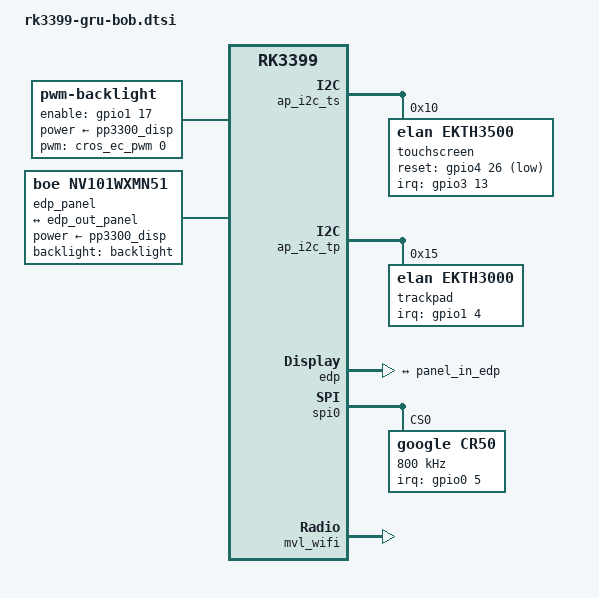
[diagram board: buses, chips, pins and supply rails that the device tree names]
/*
 * Google Gru-Bob board device tree source
 *
 * Copyright 2016 Google, Inc
 *
 * This file is dual-licensed: you can use it either under the terms
 * of the GPL or the X11 license, at your option. Note that this dual
 * licensing only applies to this file, and not this project as a
 * whole.
 *
 *  a) This file is free software; you can redistribute it and/or
 *     modify it under the terms of the GNU General Public License as
 *     published by the Free Software Foundation; either version 2 of the
 *     License, or (at your option) any later version.
 *
 *     This file is distributed in the hope that it will be useful,
 *     but WITHOUT ANY WARRANTY; without even the implied warranty of
 *     MERCHANTABILITY or FITNESS FOR A PARTICULAR PURPOSE.  See the
 *     GNU General Public License for more details.
 *
 *  Or, alternatively,
 *
 *  b) Permission is hereby granted, free of charge, to any person
 *     obtaining a copy of this software and associated documentation
 *     files (the "Software"), to deal in the Software without
 *     restriction, including without limitation the rights to use,
 *     copy, modify, merge, publish, distribute, sublicense, and/or
 *     sell copies of the Software, and to permit persons to whom the
 *     Software is furnished to do so, subject to the following
 *     conditions:
 *
 *     The above copyright notice and this permission notice shall be
 *     included in all copies or substantial portions of the Software.
 *
 *     THE SOFTWARE IS PROVIDED "AS IS", WITHOUT WARRANTY OF ANY KIND,
 *     EXPRESS OR IMPLIED, INCLUDING BUT NOT LIMITED TO THE WARRANTIES
 *     OF MERCHANTABILITY, FITNESS FOR A PARTICULAR PURPOSE AND
 *     NONINFRINGEMENT. IN NO EVENT SHALL THE AUTHORS OR COPYRIGHT
 *     HOLDERS BE LIABLE FOR ANY CLAIM, DAMAGES OR OTHER LIABILITY,
 *     WHETHER IN AN ACTION OF CONTRACT, TORT OR OTHERWISE, ARISING
 *     FROM, OUT OF OR IN CONNECTION WITH THE SOFTWARE OR THE USE OR
 *     OTHER DEALINGS IN THE SOFTWARE.
 */

#include "rk3399-gru.dtsi"

/ {
	backlight: backlight {
		compatible = "pwm-backlight";
		pwms = <&cros_ec_pwm 0>;
		brightness-levels-scale = <0x10000>;
		default-brightness-level = <0x828f>; /* arbitrary, ~51% */
		enable-gpios = <&gpio1 17 GPIO_ACTIVE_HIGH>;
		power-supply = <&pp3300_disp>;
		pinctrl-names = "default";
		pinctrl-0 = <&bl_en>;
		pwm-delay-us = <10000>;
	};

	edp_panel: edp-panel {
		compatible = "boe,nv101wxmn51", "simple-panel";
		backlight = <&backlight>;
		power-supply = <&pp3300_disp>;

		ports {
			panel_in_edp: endpoint {
				remote-endpoint = <&edp_out_panel>;
			};
		};
	};
};

&ap_i2c_ts {
	touchscreen: touchscreen@10 {
		compatible = "elan,ekth3500";
		reg = <0x10>;

		pinctrl-names = "default";
		pinctrl-0 = <&touch_int_l &touch_reset_l>;

		interrupt-parent = <&gpio3>;
		interrupts = <13 IRQ_TYPE_LEVEL_LOW>;

		reset-gpios = <&gpio4 26 GPIO_ACTIVE_LOW>;
	};
};

&ap_i2c_tp {
	trackpad: trackpad@15 {
		compatible = "elan,ekth3000";
		reg = <0x15>;

		pinctrl-names = "default";
		pinctrl-0 = <&trackpad_int_l>;

		interrupt-parent = <&gpio1>;
		interrupts = <4 IRQ_TYPE_LEVEL_LOW>;

		wakeup-source;
	};
};

&edp {
	status = "okay";

	ports {
		edp_out: port@1 {
			reg = <1>;
			#address-cells = <1>;
			#size-cells = <0>;

			edp_out_panel: endpoint@0 {
				reg = <0>;
				remote-endpoint = <&panel_in_edp>;
			};
		};
	};
};

&spi0 {
	status = "okay";

	cr50@0 {
		compatible = "google,cr50";

		interrupt-parent = <&gpio0>;
		interrupts = <5 IRQ_TYPE_EDGE_RISING>;

		pinctrl-names = "default";
		pinctrl-0 = <&h1_int_od_l>;

		reg = <0>;
		spi-max-frequency = <800000>;
	};
};

&target {
	temperature = <70000>;
};

&threshold {
	temperature = <65000>;
};

&mvl_wifi {
	marvell,caldata_00_txpwrlimit_2g_cfg_set = /bits/ 8 <
0x01 0x00 0x06 0x00 0x30 0x02 0x89 0x01 0x24 0x00 0x67 0x09 0x14 0x01 0x00 0x0d
0x01 0x0d 0x02 0x0d 0x03 0x0d 0x04 0x0d 0x05 0x0d 0x06 0x0d 0x07 0x0d 0x08 0x0d
0x09 0x0d 0x0a 0x0d 0x0b 0x0d 0x0c 0x0d 0x0d 0x0d 0x0e 0x0d 0x0f 0x0d 0x89 0x01
0x24 0x00 0x67 0x09 0x14 0x02 0x00 0x0d 0x01 0x0d 0x02 0x0d 0x03 0x0d 0x04 0x0d
0x05 0x0d 0x06 0x0d 0x07 0x0d 0x08 0x0d 0x09 0x0d 0x0a 0x0d 0x0b 0x0d 0x0c 0x0d
0x0d 0x0d 0x0e 0x0d 0x0f 0x0d 0x89 0x01 0x24 0x00 0x67 0x09 0x14 0x03 0x00 0x0d
0x01 0x0d 0x02 0x0d 0x03 0x0d 0x04 0x0d 0x05 0x0d 0x06 0x0d 0x07 0x0d 0x08 0x0d
0x09 0x0d 0x0a 0x0d 0x0b 0x0d 0x0c 0x0d 0x0d 0x0d 0x0e 0x0d 0x0f 0x0d 0x89 0x01
0x24 0x00 0x67 0x09 0x14 0x04 0x00 0x0d 0x01 0x0d 0x02 0x0d 0x03 0x0d 0x04 0x0d
0x05 0x0d 0x06 0x0d 0x07 0x0d 0x08 0x0d 0x09 0x0d 0x0a 0x0d 0x0b 0x0d 0x0c 0x0d
0x0d 0x0d 0x0e 0x0d 0x0f 0x0d 0x89 0x01 0x24 0x00 0x67 0x09 0x14 0x05 0x00 0x0d
0x01 0x0d 0x02 0x0d 0x03 0x0d 0x04 0x0d 0x05 0x0d 0x06 0x0d 0x07 0x0d 0x08 0x0d
0x09 0x0d 0x0a 0x0d 0x0b 0x0d 0x0c 0x0d 0x0d 0x0d 0x0e 0x0d 0x0f 0x0d 0x89 0x01
0x24 0x00 0x67 0x09 0x14 0x06 0x00 0x0d 0x01 0x0d 0x02 0x0d 0x03 0x0d 0x04 0x0d
0x05 0x0d 0x06 0x0d 0x07 0x0d 0x08 0x0d 0x09 0x0d 0x0a 0x0d 0x0b 0x0d 0x0c 0x0d
0x0d 0x0d 0x0e 0x0d 0x0f 0x0d 0x89 0x01 0x24 0x00 0x67 0x09 0x14 0x07 0x00 0x0d
0x01 0x0d 0x02 0x0d 0x03 0x0d 0x04 0x0d 0x05 0x0d 0x06 0x0d 0x07 0x0d 0x08 0x0d
0x09 0x0d 0x0a 0x0d 0x0b 0x0d 0x0c 0x0d 0x0d 0x0d 0x0e 0x0d 0x0f 0x0d 0x89 0x01
0x24 0x00 0x67 0x09 0x14 0x08 0x00 0x0d 0x01 0x0d 0x02 0x0d 0x03 0x0d 0x04 0x0d
0x05 0x0d 0x06 0x0d 0x07 0x0d 0x08 0x0d 0x09 0x0d 0x0a 0x0d 0x0b 0x0d 0x0c 0x0d
0x0d 0x0d 0x0e 0x0d 0x0f 0x0d 0x89 0x01 0x24 0x00 0x67 0x09 0x14 0x09 0x00 0x0d
0x01 0x0d 0x02 0x0d 0x03 0x0d 0x04 0x0d 0x05 0x0d 0x06 0x0d 0x07 0x0d 0x08 0x0d
0x09 0x0d 0x0a 0x0d 0x0b 0x0d 0x0c 0x0d 0x0d 0x0d 0x0e 0x0d 0x0f 0x0d 0x89 0x01
0x24 0x00 0x67 0x09 0x14 0x0a 0x00 0x0d 0x01 0x0d 0x02 0x0d 0x03 0x0d 0x04 0x0d
0x05 0x0d 0x06 0x0d 0x07 0x0d 0x08 0x0d 0x09 0x0d 0x0a 0x0d 0x0b 0x0d 0x0c 0x0d
0x0d 0x0d 0x0e 0x0d 0x0f 0x0d 0x89 0x01 0x24 0x00 0x67 0x09 0x14 0x0b 0x00 0x0d
0x01 0x0d 0x02 0x0d 0x03 0x0d 0x04 0x0d 0x05 0x0d 0x06 0x0d 0x07 0x0d 0x08 0x0d
0x09 0x0d 0x0a 0x0d 0x0b 0x0d 0x0c 0x0d 0x0d 0x0d 0x0e 0x0d 0x0f 0x0d 0x89 0x01
0x24 0x00 0x67 0x09 0x14 0x0c 0x00 0x0d 0x01 0x0d 0x02 0x0d 0x03 0x0d 0x04 0x0d
0x05 0x0d 0x06 0x0d 0x07 0x0d 0x08 0x0d 0x09 0x0d 0x0a 0x0d 0x0b 0x0d 0x0c 0x0d
0x0d 0x0d 0x0e 0x0d 0x0f 0x0d 0x89 0x01 0x24 0x00 0x67 0x09 0x14 0x0d 0x00 0x0d
0x01 0x0d 0x02 0x0d 0x03 0x0d 0x04 0x0d 0x05 0x0d 0x06 0x0d 0x07 0x0d 0x08 0x0d
0x09 0x0d 0x0a 0x0d 0x0b 0x0d 0x0c 0x0d 0x0d 0x0d 0x0e 0x0d 0x0f 0x0d 0x89 0x01
0x24 0x00 0x67 0x09 0x14 0x0e 0x00 0x0d 0x01 0x0d 0x02 0x0d 0x03 0x0d 0x04 0x0d
0x05 0x0d 0x06 0x0d 0x07 0x0d 0x08 0x0d 0x09 0x0d 0x0a 0x0d 0x0b 0x0d 0x0c 0x0d
0x0d 0x0d 0x0e 0x0d 0x0f 0x0d
	>;

	marvell,caldata_00_txpwrlimit_5g_cfg_set_sub0 = /bits/ 8 <
0x01 0x00 0x06 0x00 0x04 0x02 0x89 0x01 0x3c 0x00 0x88 0x13 0x14 0x24 0x00 0x0a
0x01 0x0a 0x02 0x0a 0x03 0x0a 0x04 0x0a 0x05 0x0a 0x06 0x0a 0x07 0x0a 0x08 0x0a
0x09 0x0a 0x0a 0x0a 0x0b 0x0a 0x0c 0x0a 0x0d 0x0a 0x0e 0x0a 0x0f 0x0a 0x10 0x0a
0x11 0x0a 0x12 0x0a 0x13 0x0a 0x14 0x0a 0x15 0x0a 0x16 0x0a 0x17 0x0a 0x18 0x0a
0x19 0x0a 0x1a 0x0a 0x1b 0x0a 0x89 0x01 0x3c 0x00 0x88 0x13 0x14 0x28 0x00 0x0a
0x01 0x0a 0x02 0x0a 0x03 0x0a 0x04 0x0a 0x05 0x0a 0x06 0x0a 0x07 0x0a 0x08 0x0a
0x09 0x0a 0x0a 0x0a 0x0b 0x0a 0x0c 0x0a 0x0d 0x0a 0x0e 0x0a 0x0f 0x0a 0x10 0x0a
0x11 0x0a 0x12 0x0a 0x13 0x0a 0x14 0x0a 0x15 0x0a 0x16 0x0a 0x17 0x0a 0x18 0x0a
0x19 0x0a 0x1a 0x0a 0x1b 0x0a 0x89 0x01 0x3c 0x00 0x88 0x13 0x14 0x2c 0x00 0x0a
0x01 0x0a 0x02 0x0a 0x03 0x0a 0x04 0x0a 0x05 0x0a 0x06 0x0a 0x07 0x0a 0x08 0x0a
0x09 0x0a 0x0a 0x0a 0x0b 0x0a 0x0c 0x0a 0x0d 0x0a 0x0e 0x0a 0x0f 0x0a 0x10 0x0a
0x11 0x0a 0x12 0x0a 0x13 0x0a 0x14 0x0a 0x15 0x0a 0x16 0x0a 0x17 0x0a 0x18 0x0a
0x19 0x0a 0x1a 0x0a 0x1b 0x0a 0x89 0x01 0x3c 0x00 0x88 0x13 0x14 0x30 0x00 0x0a
0x01 0x0a 0x02 0x0a 0x03 0x0a 0x04 0x0a 0x05 0x0a 0x06 0x0a 0x07 0x0a 0x08 0x0a
0x09 0x0a 0x0a 0x0a 0x0b 0x0a 0x0c 0x0a 0x0d 0x0a 0x0e 0x0a 0x0f 0x0a 0x10 0x0a
0x11 0x0a 0x12 0x0a 0x13 0x0a 0x14 0x0a 0x15 0x0a 0x16 0x0a 0x17 0x0a 0x18 0x0a
0x19 0x0a 0x1a 0x0a 0x1b 0x0a 0x89 0x01 0x3c 0x00 0x88 0x13 0x14 0x34 0x00 0x0a
0x01 0x0a 0x02 0x0a 0x03 0x0a 0x04 0x0a 0x05 0x0a 0x06 0x0a 0x07 0x0a 0x08 0x0a
0x09 0x0a 0x0a 0x0a 0x0b 0x0a 0x0c 0x0a 0x0d 0x0a 0x0e 0x0a 0x0f 0x0a 0x10 0x0a
0x11 0x0a 0x12 0x0a 0x13 0x0a 0x14 0x0a 0x15 0x0a 0x16 0x0a 0x17 0x0a 0x18 0x0a
0x19 0x0a 0x1a 0x0a 0x1b 0x0a 0x89 0x01 0x3c 0x00 0x88 0x13 0x14 0x38 0x00 0x0a
0x01 0x0a 0x02 0x0a 0x03 0x0a 0x04 0x0a 0x05 0x0a 0x06 0x0a 0x07 0x0a 0x08 0x0a
0x09 0x0a 0x0a 0x0a 0x0b 0x0a 0x0c 0x0a 0x0d 0x0a 0x0e 0x0a 0x0f 0x0a 0x10 0x0a
0x11 0x0a 0x12 0x0a 0x13 0x0a 0x14 0x0a 0x15 0x0a 0x16 0x0a 0x17 0x0a 0x18 0x0a
0x19 0x0a 0x1a 0x0a 0x1b 0x0a 0x89 0x01 0x3c 0x00 0x88 0x13 0x14 0x3c 0x00 0x0a
0x01 0x0a 0x02 0x0a 0x03 0x0a 0x04 0x0a 0x05 0x0a 0x06 0x0a 0x07 0x0a 0x08 0x0a
0x09 0x0a 0x0a 0x0a 0x0b 0x0a 0x0c 0x0a 0x0d 0x0a 0x0e 0x0a 0x0f 0x0a 0x10 0x0a
0x11 0x0a 0x12 0x0a 0x13 0x0a 0x14 0x0a 0x15 0x0a 0x16 0x0a 0x17 0x0a 0x18 0x0a
0x19 0x0a 0x1a 0x0a 0x1b 0x0a 0x89 0x01 0x3c 0x00 0x88 0x13 0x14 0x40 0x00 0x0a
0x01 0x0a 0x02 0x0a 0x03 0x0a 0x04 0x0a 0x05 0x0a 0x06 0x0a 0x07 0x0a 0x08 0x0a
0x09 0x0a 0x0a 0x0a 0x0b 0x0a 0x0c 0x0a 0x0d 0x0a 0x0e 0x0a 0x0f 0x0a 0x10 0x0a
0x11 0x0a 0x12 0x0a 0x13 0x0a 0x14 0x0a 0x15 0x0a 0x16 0x0a 0x17 0x0a 0x18 0x0a
0x19 0x0a 0x1a 0x0a 0x1b 0x0a
	>;

	marvell,caldata_00_txpwrlimit_5g_cfg_set_sub1 = /bits/ 8 <
0x01 0x00 0x06 0x00 0x04 0x03 0x89 0x01 0x3c 0x00 0x88 0x13 0x14 0x64 0x00 0x0a
0x01 0x0a 0x02 0x0a 0x03 0x0a 0x04 0x0a 0x05 0x0a 0x06 0x0a 0x07 0x0a 0x08 0x0a
0x09 0x0a 0x0a 0x0a 0x0b 0x0a 0x0c 0x0a 0x0d 0x0a 0x0e 0x0a 0x0f 0x0a 0x10 0x0a
0x11 0x0a 0x12 0x0a 0x13 0x0a 0x14 0x0a 0x15 0x0a 0x16 0x0a 0x17 0x0a 0x18 0x0a
0x19 0x0a 0x1a 0x0a 0x1b 0x0a 0x89 0x01 0x3c 0x00 0x88 0x13 0x14 0x68 0x00 0x0a
0x01 0x0a 0x02 0x0a 0x03 0x0a 0x04 0x0a 0x05 0x0a 0x06 0x0a 0x07 0x0a 0x08 0x0a
0x09 0x0a 0x0a 0x0a 0x0b 0x0a 0x0c 0x0a 0x0d 0x0a 0x0e 0x0a 0x0f 0x0a 0x10 0x0a
0x11 0x0a 0x12 0x0a 0x13 0x0a 0x14 0x0a 0x15 0x0a 0x16 0x0a 0x17 0x0a 0x18 0x0a
0x19 0x0a 0x1a 0x0a 0x1b 0x0a 0x89 0x01 0x3c 0x00 0x88 0x13 0x14 0x6c 0x00 0x0a
0x01 0x0a 0x02 0x0a 0x03 0x0a 0x04 0x0a 0x05 0x0a 0x06 0x0a 0x07 0x0a 0x08 0x0a
0x09 0x0a 0x0a 0x0a 0x0b 0x0a 0x0c 0x0a 0x0d 0x0a 0x0e 0x0a 0x0f 0x0a 0x10 0x0a
0x11 0x0a 0x12 0x0a 0x13 0x0a 0x14 0x0a 0x15 0x0a 0x16 0x0a 0x17 0x0a 0x18 0x0a
0x19 0x0a 0x1a 0x0a 0x1b 0x0a 0x89 0x01 0x3c 0x00 0x88 0x13 0x14 0x70 0x00 0x0a
0x01 0x0a 0x02 0x0a 0x03 0x0a 0x04 0x0a 0x05 0x0a 0x06 0x0a 0x07 0x0a 0x08 0x0a
0x09 0x0a 0x0a 0x0a 0x0b 0x0a 0x0c 0x0a 0x0d 0x0a 0x0e 0x0a 0x0f 0x0a 0x10 0x0a
0x11 0x0a 0x12 0x0a 0x13 0x0a 0x14 0x0a 0x15 0x0a 0x16 0x0a 0x17 0x0a 0x18 0x0a
0x19 0x0a 0x1a 0x0a 0x1b 0x0a 0x89 0x01 0x3c 0x00 0x88 0x13 0x14 0x74 0x00 0x0a
0x01 0x0a 0x02 0x0a 0x03 0x0a 0x04 0x0a 0x05 0x0a 0x06 0x0a 0x07 0x0a 0x08 0x0a
0x09 0x0a 0x0a 0x0a 0x0b 0x0a 0x0c 0x0a 0x0d 0x0a 0x0e 0x0a 0x0f 0x0a 0x10 0x0a
0x11 0x0a 0x12 0x0a 0x13 0x0a 0x14 0x0a 0x15 0x0a 0x16 0x0a 0x17 0x0a 0x18 0x0a
0x19 0x0a 0x1a 0x0a 0x1b 0x0a 0x89 0x01 0x3c 0x00 0x88 0x13 0x14 0x78 0x00 0x0a
0x01 0x0a 0x02 0x0a 0x03 0x0a 0x04 0x0a 0x05 0x0a 0x06 0x0a 0x07 0x0a 0x08 0x0a
0x09 0x0a 0x0a 0x0a 0x0b 0x0a 0x0c 0x0a 0x0d 0x0a 0x0e 0x0a 0x0f 0x0a 0x10 0x0a
0x11 0x0a 0x12 0x0a 0x13 0x0a 0x14 0x0a 0x15 0x0a 0x16 0x0a 0x17 0x0a 0x18 0x0a
0x19 0x0a 0x1a 0x0a 0x1b 0x0a 0x89 0x01 0x3c 0x00 0x88 0x13 0x14 0x7c 0x00 0x0a
0x01 0x0a 0x02 0x0a 0x03 0x0a 0x04 0x0a 0x05 0x0a 0x06 0x0a 0x07 0x0a 0x08 0x0a
0x09 0x0a 0x0a 0x0a 0x0b 0x0a 0x0c 0x0a 0x0d 0x0a 0x0e 0x0a 0x0f 0x0a 0x10 0x0a
0x11 0x0a 0x12 0x0a 0x13 0x0a 0x14 0x0a 0x15 0x0a 0x16 0x0a 0x17 0x0a 0x18 0x0a
0x19 0x0a 0x1a 0x0a 0x1b 0x0a 0x89 0x01 0x3c 0x00 0x88 0x13 0x14 0x80 0x00 0x0a
0x01 0x0a 0x02 0x0a 0x03 0x0a 0x04 0x0a 0x05 0x0a 0x06 0x0a 0x07 0x0a 0x08 0x0a
0x09 0x0a 0x0a 0x0a 0x0b 0x0a 0x0c 0x0a 0x0d 0x0a 0x0e 0x0a 0x0f 0x0a 0x10 0x0a
0x11 0x0a 0x12 0x0a 0x13 0x0a 0x14 0x0a 0x15 0x0a 0x16 0x0a 0x17 0x0a 0x18 0x0a
0x19 0x0a 0x1a 0x0a 0x1b 0x0a 0x89 0x01 0x3c 0x00 0x88 0x13 0x14 0x84 0x00 0x0a
0x01 0x0a 0x02 0x0a 0x03 0x0a 0x04 0x0a 0x05 0x0a 0x06 0x0a 0x07 0x0a 0x08 0x0a
0x09 0x0a 0x0a 0x0a 0x0b 0x0a 0x0c 0x0a 0x0d 0x0a 0x0e 0x0a 0x0f 0x0a 0x10 0x0a
0x11 0x0a 0x12 0x0a 0x13 0x0a 0x14 0x0a 0x15 0x0a 0x16 0x0a 0x17 0x0a 0x18 0x0a
0x19 0x0a 0x1a 0x0a 0x1b 0x0a 0x89 0x01 0x3c 0x00 0x88 0x13 0x14 0x88 0x00 0x0a
0x01 0x0a 0x02 0x0a 0x03 0x0a 0x04 0x0a 0x05 0x0a 0x06 0x0a 0x07 0x0a 0x08 0x0a
0x09 0x0a 0x0a 0x0a 0x0b 0x0a 0x0c 0x0a 0x0d 0x0a 0x0e 0x0a 0x0f 0x0a 0x10 0x0a
0x11 0x0a 0x12 0x0a 0x13 0x0a 0x14 0x0a 0x15 0x0a 0x16 0x0a 0x17 0x0a 0x18 0x0a
0x19 0x0a 0x1a 0x0a 0x1b 0x0a 0x89 0x01 0x3c 0x00 0x88 0x13 0x14 0x8c 0x00 0x0a
0x01 0x0a 0x02 0x0a 0x03 0x0a 0x04 0x0a 0x05 0x0a 0x06 0x0a 0x07 0x0a 0x08 0x0a
0x09 0x0a 0x0a 0x0a 0x0b 0x0a 0x0c 0x0a 0x0d 0x0a 0x0e 0x0a 0x0f 0x0a 0x10 0x0a
0x11 0x0a 0x12 0x0a 0x13 0x0a 0x14 0x0a 0x15 0x0a 0x16 0x0a 0x17 0x0a 0x18 0x0a
0x19 0x0a 0x1a 0x0a 0x1b 0x0a 0x89 0x01 0x3c 0x00 0x88 0x13 0x14 0x90 0x00 0x0a
0x01 0x0a 0x02 0x0a 0x03 0x0a 0x04 0x0a 0x05 0x0a 0x06 0x0a 0x07 0x0a 0x08 0x0a
0x09 0x0a 0x0a 0x0a 0x0b 0x0a 0x0c 0x0a 0x0d 0x0a 0x0e 0x0a 0x0f 0x0a 0x10 0x0a
0x11 0x0a 0x12 0x0a 0x13 0x0a 0x14 0x0a 0x15 0x0a 0x16 0x0a 0x17 0x0a 0x18 0x0a
0x19 0x0a 0x1a 0x0a 0x1b 0x0a
	>;

	marvell,caldata_00_txpwrlimit_5g_cfg_set_sub2 = /bits/ 8 <
0x01 0x00 0x06 0x00 0x44 0x01 0x89 0x01 0x3c 0x00 0x88 0x13 0x14 0x95 0x00 0x0a
0x01 0x0a 0x02 0x0a 0x03 0x0a 0x04 0x0a 0x05 0x0a 0x06 0x0a 0x07 0x0a 0x08 0x0a
0x09 0x0a 0x0a 0x0a 0x0b 0x0a 0x0c 0x0a 0x0d 0x0a 0x0e 0x0a 0x0f 0x0a 0x10 0x0a
0x11 0x0a 0x12 0x0a 0x13 0x0a 0x14 0x0a 0x15 0x0a 0x16 0x0a 0x17 0x0a 0x18 0x0a
0x19 0x0a 0x1a 0x0a 0x1b 0x0a 0x89 0x01 0x3c 0x00 0x88 0x13 0x14 0x99 0x00 0x0a
0x01 0x0a 0x02 0x0a 0x03 0x0a 0x04 0x0a 0x05 0x0a 0x06 0x0a 0x07 0x0a 0x08 0x0a
0x09 0x0a 0x0a 0x0a 0x0b 0x0a 0x0c 0x0a 0x0d 0x0a 0x0e 0x0a 0x0f 0x0a 0x10 0x0a
0x11 0x0a 0x12 0x0a 0x13 0x0a 0x14 0x0a 0x15 0x0a 0x16 0x0a 0x17 0x0a 0x18 0x0a
0x19 0x0a 0x1a 0x0a 0x1b 0x0a 0x89 0x01 0x3c 0x00 0x88 0x13 0x14 0x9d 0x00 0x0a
0x01 0x0a 0x02 0x0a 0x03 0x0a 0x04 0x0a 0x05 0x0a 0x06 0x0a 0x07 0x0a 0x08 0x0a
0x09 0x0a 0x0a 0x0a 0x0b 0x0a 0x0c 0x0a 0x0d 0x0a 0x0e 0x0a 0x0f 0x0a 0x10 0x0a
0x11 0x0a 0x12 0x0a 0x13 0x0a 0x14 0x0a 0x15 0x0a 0x16 0x0a 0x17 0x0a 0x18 0x0a
0x19 0x0a 0x1a 0x0a 0x1b 0x0a 0x89 0x01 0x3c 0x00 0x88 0x13 0x14 0xa1 0x00 0x0a
0x01 0x0a 0x02 0x0a 0x03 0x0a 0x04 0x0a 0x05 0x0a 0x06 0x0a 0x07 0x0a 0x08 0x0a
0x09 0x0a 0x0a 0x0a 0x0b 0x0a 0x0c 0x0a 0x0d 0x0a 0x0e 0x0a 0x0f 0x0a 0x10 0x0a
0x11 0x0a 0x12 0x0a 0x13 0x0a 0x14 0x0a 0x15 0x0a 0x16 0x0a 0x17 0x0a 0x18 0x0a
0x19 0x0a 0x1a 0x0a 0x1b 0x0a 0x89 0x01 0x3c 0x00 0x88 0x13 0x14 0xa5 0x00 0x0a
0x01 0x0a 0x02 0x0a 0x03 0x0a 0x04 0x0a 0x05 0x0a 0x06 0x0a 0x07 0x0a 0x08 0x0a
0x09 0x0a 0x0a 0x0a 0x0b 0x0a 0x0c 0x0a 0x0d 0x0a 0x0e 0x0a 0x0f 0x0a 0x10 0x0a
0x11 0x0a 0x12 0x0a 0x13 0x0a 0x14 0x0a 0x15 0x0a 0x16 0x0a 0x17 0x0a 0x18 0x0a
0x19 0x0a 0x1a 0x0a 0x1b 0x0a
	>;

	marvell,caldata_00_txpwrlimit_5g_cfg_set_sub3 = /bits/ 8 <
0x01 0x00 0x06 0x00 0x84 0x03 0x89 0x01 0x3c 0x00 0xa0 0x0f 0x14 0xb7 0x00 0x0a
0x01 0x0a 0x02 0x0a 0x03 0x0a 0x04 0x0a 0x05 0x0a 0x06 0x0a 0x07 0x0a 0x08 0x0a
0x09 0x0a 0x0a 0x0a 0x0b 0x0a 0x0c 0x0a 0x0d 0x0a 0x0e 0x0a 0x0f 0x0a 0x10 0x0a
0x11 0x0a 0x12 0x0a 0x13 0x0a 0x14 0x0a 0x15 0x0a 0x16 0x0a 0x17 0x0a 0x18 0x0a
0x19 0x0a 0x1a 0x0a 0x1b 0x0a 0x89 0x01 0x3c 0x00 0xa0 0x0f 0x14 0xb8 0x00 0x0a
0x01 0x0a 0x02 0x0a 0x03 0x0a 0x04 0x0a 0x05 0x0a 0x06 0x0a 0x07 0x0a 0x08 0x0a
0x09 0x0a 0x0a 0x0a 0x0b 0x0a 0x0c 0x0a 0x0d 0x0a 0x0e 0x0a 0x0f 0x0a 0x10 0x0a
0x11 0x0a 0x12 0x0a 0x13 0x0a 0x14 0x0a 0x15 0x0a 0x16 0x0a 0x17 0x0a 0x18 0x0a
0x19 0x0a 0x1a 0x0a 0x1b 0x0a 0x89 0x01 0x3c 0x00 0xa0 0x0f 0x14 0xb9 0x00 0x0a
0x01 0x0a 0x02 0x0a 0x03 0x0a 0x04 0x0a 0x05 0x0a 0x06 0x0a 0x07 0x0a 0x08 0x0a
0x09 0x0a 0x0a 0x0a 0x0b 0x0a 0x0c 0x0a 0x0d 0x0a 0x0e 0x0a 0x0f 0x0a 0x10 0x0a
0x11 0x0a 0x12 0x0a 0x13 0x0a 0x14 0x0a 0x15 0x0a 0x16 0x0a 0x17 0x0a 0x18 0x0a
0x19 0x0a 0x1a 0x0a 0x1b 0x0a 0x89 0x01 0x3c 0x00 0xa0 0x0f 0x14 0xbb 0x00 0x0a
0x01 0x0a 0x02 0x0a 0x03 0x0a 0x04 0x0a 0x05 0x0a 0x06 0x0a 0x07 0x0a 0x08 0x0a
0x09 0x0a 0x0a 0x0a 0x0b 0x0a 0x0c 0x0a 0x0d 0x0a 0x0e 0x0a 0x0f 0x0a 0x10 0x0a
0x11 0x0a 0x12 0x0a 0x13 0x0a 0x14 0x0a 0x15 0x0a 0x16 0x0a 0x17 0x0a 0x18 0x0a
0x19 0x0a 0x1a 0x0a 0x1b 0x0a 0x89 0x01 0x3c 0x00 0xa0 0x0f 0x14 0xbc 0x00 0x0a
0x01 0x0a 0x02 0x0a 0x03 0x0a 0x04 0x0a 0x05 0x0a 0x06 0x0a 0x07 0x0a 0x08 0x0a
0x09 0x0a 0x0a 0x0a 0x0b 0x0a 0x0c 0x0a 0x0d 0x0a 0x0e 0x0a 0x0f 0x0a 0x10 0x0a
0x11 0x0a 0x12 0x0a 0x13 0x0a 0x14 0x0a 0x15 0x0a 0x16 0x0a 0x17 0x0a 0x18 0x0a
0x19 0x0a 0x1a 0x0a 0x1b 0x0a 0x89 0x01 0x3c 0x00 0xa0 0x0f 0x14 0xbd 0x00 0x0a
0x01 0x0a 0x02 0x0a 0x03 0x0a 0x04 0x0a 0x05 0x0a 0x06 0x0a 0x07 0x0a 0x08 0x0a
0x09 0x0a 0x0a 0x0a 0x0b 0x0a 0x0c 0x0a 0x0d 0x0a 0x0e 0x0a 0x0f 0x0a 0x10 0x0a
0x11 0x0a 0x12 0x0a 0x13 0x0a 0x14 0x0a 0x15 0x0a 0x16 0x0a 0x17 0x0a 0x18 0x0a
0x19 0x0a 0x1a 0x0a 0x1b 0x0a 0x89 0x01 0x3c 0x00 0xa0 0x0f 0x14 0xc0 0x00 0x0a
0x01 0x0a 0x02 0x0a 0x03 0x0a 0x04 0x0a 0x05 0x0a 0x06 0x0a 0x07 0x0a 0x08 0x0a
0x09 0x0a 0x0a 0x0a 0x0b 0x0a 0x0c 0x0a 0x0d 0x0a 0x0e 0x0a 0x0f 0x0a 0x10 0x0a
0x11 0x0a 0x12 0x0a 0x13 0x0a 0x14 0x0a 0x15 0x0a 0x16 0x0a 0x17 0x0a 0x18 0x0a
0x19 0x0a 0x1a 0x0a 0x1b 0x0a 0x89 0x01 0x3c 0x00 0xa0 0x0f 0x14 0xc4 0x00 0x0a
0x01 0x0a 0x02 0x0a 0x03 0x0a 0x04 0x0a 0x05 0x0a 0x06 0x0a 0x07 0x0a 0x08 0x0a
0x09 0x0a 0x0a 0x0a 0x0b 0x0a 0x0c 0x0a 0x0d 0x0a 0x0e 0x0a 0x0f 0x0a 0x10 0x0a
0x11 0x0a 0x12 0x0a 0x13 0x0a 0x14 0x0a 0x15 0x0a 0x16 0x0a 0x17 0x0a 0x18 0x0a
0x19 0x0a 0x1a 0x0a 0x1b 0x0a 0x89 0x01 0x3c 0x00 0x88 0x13 0x14 0x07 0x00 0x0a
0x01 0x0a 0x02 0x0a 0x03 0x0a 0x04 0x0a 0x05 0x0a 0x06 0x0a 0x07 0x0a 0x08 0x0a
0x09 0x0a 0x0a 0x0a 0x0b 0x0a 0x0c 0x0a 0x0d 0x0a 0x0e 0x0a 0x0f 0x0a 0x10 0x0a
0x11 0x0a 0x12 0x0a 0x13 0x0a 0x14 0x0a 0x15 0x0a 0x16 0x0a 0x17 0x0a 0x18 0x0a
0x19 0x0a 0x1a 0x0a 0x1b 0x0a 0x89 0x01 0x3c 0x00 0x88 0x13 0x14 0x08 0x00 0x0a
0x01 0x0a 0x02 0x0a 0x03 0x0a 0x04 0x0a 0x05 0x0a 0x06 0x0a 0x07 0x0a 0x08 0x0a
0x09 0x0a 0x0a 0x0a 0x0b 0x0a 0x0c 0x0a 0x0d 0x0a 0x0e 0x0a 0x0f 0x0a 0x10 0x0a
0x11 0x0a 0x12 0x0a 0x13 0x0a 0x14 0x0a 0x15 0x0a 0x16 0x0a 0x17 0x0a 0x18 0x0a
0x19 0x0a 0x1a 0x0a 0x1b 0x0a 0x89 0x01 0x3c 0x00 0x88 0x13 0x14 0x0b 0x00 0x0a
0x01 0x0a 0x02 0x0a 0x03 0x0a 0x04 0x0a 0x05 0x0a 0x06 0x0a 0x07 0x0a 0x08 0x0a
0x09 0x0a 0x0a 0x0a 0x0b 0x0a 0x0c 0x0a 0x0d 0x0a 0x0e 0x0a 0x0f 0x0a 0x10 0x0a
0x11 0x0a 0x12 0x0a 0x13 0x0a 0x14 0x0a 0x15 0x0a 0x16 0x0a 0x17 0x0a 0x18 0x0a
0x19 0x0a 0x1a 0x0a 0x1b 0x0a 0x89 0x01 0x3c 0x00 0x88 0x13 0x14 0x0c 0x00 0x0a
0x01 0x0a 0x02 0x0a 0x03 0x0a 0x04 0x0a 0x05 0x0a 0x06 0x0a 0x07 0x0a 0x08 0x0a
0x09 0x0a 0x0a 0x0a 0x0b 0x0a 0x0c 0x0a 0x0d 0x0a 0x0e 0x0a 0x0f 0x0a 0x10 0x0a
0x11 0x0a 0x12 0x0a 0x13 0x0a 0x14 0x0a 0x15 0x0a 0x16 0x0a 0x17 0x0a 0x18 0x0a
0x19 0x0a 0x1a 0x0a 0x1b 0x0a 0x89 0x01 0x3c 0x00 0x88 0x13 0x14 0x10 0x00 0x0a
0x01 0x0a 0x02 0x0a 0x03 0x0a 0x04 0x0a 0x05 0x0a 0x06 0x0a 0x07 0x0a 0x08 0x0a
0x09 0x0a 0x0a 0x0a 0x0b 0x0a 0x0c 0x0a 0x0d 0x0a 0x0e 0x0a 0x0f 0x0a 0x10 0x0a
0x11 0x0a 0x12 0x0a 0x13 0x0a 0x14 0x0a 0x15 0x0a 0x16 0x0a 0x17 0x0a 0x18 0x0a
0x19 0x0a 0x1a 0x0a 0x1b 0x0a 0x89 0x01 0x3c 0x00 0x88 0x13 0x14 0x22 0x00 0x0a
0x01 0x0a 0x02 0x0a 0x03 0x0a 0x04 0x0a 0x05 0x0a 0x06 0x0a 0x07 0x0a 0x08 0x0a
0x09 0x0a 0x0a 0x0a 0x0b 0x0a 0x0c 0x0a 0x0d 0x0a 0x0e 0x0a 0x0f 0x0a 0x10 0x0a
0x11 0x0a 0x12 0x0a 0x13 0x0a 0x14 0x0a 0x15 0x0a 0x16 0x0a 0x17 0x0a 0x18 0x0a
0x19 0x0a 0x1a 0x0a 0x1b 0x0a
	>;

	marvell,caldata_01_txpwrlimit_2g_cfg_set = /bits/ 8 <
0x01 0x00 0x06 0x00 0x30 0x02 0x89 0x01 0x24 0x00 0x67 0x09 0x14 0x01 0x00 0x0f
0x01 0x0f 0x02 0x0f 0x03 0x0f 0x04 0x0f 0x05 0x0f 0x06 0x0f 0x07 0x0f 0x08 0x0f
0x09 0x0f 0x0a 0x0f 0x0b 0x0f 0x0c 0x0f 0x0d 0x0f 0x0e 0x0f 0x0f 0x0f 0x89 0x01
0x24 0x00 0x67 0x09 0x14 0x02 0x00 0x0f 0x01 0x0f 0x02 0x0f 0x03 0x0f 0x04 0x0f
0x05 0x0f 0x06 0x0f 0x07 0x0f 0x08 0x0f 0x09 0x0f 0x0a 0x0f 0x0b 0x0f 0x0c 0x0f
0x0d 0x0f 0x0e 0x0f 0x0f 0x0f 0x89 0x01 0x24 0x00 0x67 0x09 0x14 0x03 0x00 0x0f
0x01 0x0f 0x02 0x0f 0x03 0x0f 0x04 0x0f 0x05 0x0f 0x06 0x0f 0x07 0x0f 0x08 0x0f
0x09 0x0f 0x0a 0x0f 0x0b 0x0f 0x0c 0x0f 0x0d 0x0f 0x0e 0x0f 0x0f 0x0f 0x89 0x01
0x24 0x00 0x67 0x09 0x14 0x04 0x00 0x0f 0x01 0x0f 0x02 0x0f 0x03 0x0f 0x04 0x0f
0x05 0x0f 0x06 0x0f 0x07 0x0f 0x08 0x0f 0x09 0x0f 0x0a 0x0f 0x0b 0x0f 0x0c 0x0f
0x0d 0x0f 0x0e 0x0f 0x0f 0x0f 0x89 0x01 0x24 0x00 0x67 0x09 0x14 0x05 0x00 0x0f
0x01 0x0f 0x02 0x0f 0x03 0x0f 0x04 0x0f 0x05 0x0f 0x06 0x0f 0x07 0x0f 0x08 0x0f
0x09 0x0f 0x0a 0x0f 0x0b 0x0f 0x0c 0x0f 0x0d 0x0f 0x0e 0x0f 0x0f 0x0f 0x89 0x01
0x24 0x00 0x67 0x09 0x14 0x06 0x00 0x0f 0x01 0x0f 0x02 0x0f 0x03 0x0f 0x04 0x0f
0x05 0x0f 0x06 0x0f 0x07 0x0f 0x08 0x0f 0x09 0x0f 0x0a 0x0f 0x0b 0x0f 0x0c 0x0f
0x0d 0x0f 0x0e 0x0f 0x0f 0x0f 0x89 0x01 0x24 0x00 0x67 0x09 0x14 0x07 0x00 0x0f
0x01 0x0f 0x02 0x0f 0x03 0x0f 0x04 0x0f 0x05 0x0f 0x06 0x0f 0x07 0x0f 0x08 0x0f
0x09 0x0f 0x0a 0x0f 0x0b 0x0f 0x0c 0x0f 0x0d 0x0f 0x0e 0x0f 0x0f 0x0f 0x89 0x01
0x24 0x00 0x67 0x09 0x14 0x08 0x00 0x0f 0x01 0x0f 0x02 0x0f 0x03 0x0f 0x04 0x0f
0x05 0x0f 0x06 0x0f 0x07 0x0f 0x08 0x0f 0x09 0x0f 0x0a 0x0f 0x0b 0x0f 0x0c 0x0f
0x0d 0x0f 0x0e 0x0f 0x0f 0x0f 0x89 0x01 0x24 0x00 0x67 0x09 0x14 0x09 0x00 0x0f
0x01 0x0f 0x02 0x0f 0x03 0x0f 0x04 0x0f 0x05 0x0f 0x06 0x0f 0x07 0x0f 0x08 0x0f
0x09 0x0f 0x0a 0x0f 0x0b 0x0f 0x0c 0x0f 0x0d 0x0f 0x0e 0x0f 0x0f 0x0f 0x89 0x01
0x24 0x00 0x67 0x09 0x14 0x0a 0x00 0x0f 0x01 0x0f 0x02 0x0f 0x03 0x0f 0x04 0x0f
0x05 0x0f 0x06 0x0f 0x07 0x0f 0x08 0x0f 0x09 0x0f 0x0a 0x0f 0x0b 0x0f 0x0c 0x0f
0x0d 0x0f 0x0e 0x0f 0x0f 0x0f 0x89 0x01 0x24 0x00 0x67 0x09 0x14 0x0b 0x00 0x0f
0x01 0x0f 0x02 0x0f 0x03 0x0f 0x04 0x0f 0x05 0x0f 0x06 0x0f 0x07 0x0f 0x08 0x0f
0x09 0x0f 0x0a 0x0f 0x0b 0x0f 0x0c 0x0f 0x0d 0x0f 0x0e 0x0f 0x0f 0x0f 0x89 0x01
0x24 0x00 0x67 0x09 0x14 0x0c 0x00 0x0f 0x01 0x0f 0x02 0x0f 0x03 0x0f 0x04 0x0f
0x05 0x0f 0x06 0x0f 0x07 0x0f 0x08 0x0f 0x09 0x0f 0x0a 0x0f 0x0b 0x0f 0x0c 0x0f
0x0d 0x0f 0x0e 0x0f 0x0f 0x0f 0x89 0x01 0x24 0x00 0x67 0x09 0x14 0x0d 0x00 0x0f
0x01 0x0f 0x02 0x0f 0x03 0x0f 0x04 0x0f 0x05 0x0f 0x06 0x0f 0x07 0x0f 0x08 0x0f
0x09 0x0f 0x0a 0x0f 0x0b 0x0f 0x0c 0x0f 0x0d 0x0f 0x0e 0x0f 0x0f 0x0f 0x89 0x01
0x24 0x00 0x67 0x09 0x14 0x0e 0x00 0x0f 0x01 0x0f 0x02 0x0f 0x03 0x0f 0x04 0x0f
0x05 0x0f 0x06 0x0f 0x07 0x0f 0x08 0x0f 0x09 0x0f 0x0a 0x0f 0x0b 0x0f 0x0c 0x0f
0x0d 0x0f 0x0e 0x0f 0x0f 0x0f
	>;

	marvell,caldata_01_txpwrlimit_5g_cfg_set_sub0 = /bits/ 8 <
0x01 0x00 0x06 0x00 0x04 0x02 0x89 0x01 0x3c 0x00 0x88 0x13 0x14 0x24 0x00 0x0a
0x01 0x0a 0x02 0x0a 0x03 0x0a 0x04 0x0a 0x05 0x0a 0x06 0x0a 0x07 0x0a 0x08 0x0a
0x09 0x0a 0x0a 0x0a 0x0b 0x0a 0x0c 0x0a 0x0d 0x0a 0x0e 0x0a 0x0f 0x0a 0x10 0x0a
0x11 0x0a 0x12 0x0a 0x13 0x0a 0x14 0x0a 0x15 0x0a 0x16 0x0a 0x17 0x0a 0x18 0x0a
0x19 0x0a 0x1a 0x0a 0x1b 0x0a 0x89 0x01 0x3c 0x00 0x88 0x13 0x14 0x28 0x00 0x0a
0x01 0x0a 0x02 0x0a 0x03 0x0a 0x04 0x0a 0x05 0x0a 0x06 0x0a 0x07 0x0a 0x08 0x0a
0x09 0x0a 0x0a 0x0a 0x0b 0x0a 0x0c 0x0a 0x0d 0x0a 0x0e 0x0a 0x0f 0x0a 0x10 0x0a
0x11 0x0a 0x12 0x0a 0x13 0x0a 0x14 0x0a 0x15 0x0a 0x16 0x0a 0x17 0x0a 0x18 0x0a
0x19 0x0a 0x1a 0x0a 0x1b 0x0a 0x89 0x01 0x3c 0x00 0x88 0x13 0x14 0x2c 0x00 0x0a
0x01 0x0a 0x02 0x0a 0x03 0x0a 0x04 0x0a 0x05 0x0a 0x06 0x0a 0x07 0x0a 0x08 0x0a
0x09 0x0a 0x0a 0x0a 0x0b 0x0a 0x0c 0x0a 0x0d 0x0a 0x0e 0x0a 0x0f 0x0a 0x10 0x0a
0x11 0x0a 0x12 0x0a 0x13 0x0a 0x14 0x0a 0x15 0x0a 0x16 0x0a 0x17 0x0a 0x18 0x0a
0x19 0x0a 0x1a 0x0a 0x1b 0x0a 0x89 0x01 0x3c 0x00 0x88 0x13 0x14 0x30 0x00 0x0a
0x01 0x0a 0x02 0x0a 0x03 0x0a 0x04 0x0a 0x05 0x0a 0x06 0x0a 0x07 0x0a 0x08 0x0a
0x09 0x0a 0x0a 0x0a 0x0b 0x0a 0x0c 0x0a 0x0d 0x0a 0x0e 0x0a 0x0f 0x0a 0x10 0x0a
0x11 0x0a 0x12 0x0a 0x13 0x0a 0x14 0x0a 0x15 0x0a 0x16 0x0a 0x17 0x0a 0x18 0x0a
0x19 0x0a 0x1a 0x0a 0x1b 0x0a 0x89 0x01 0x3c 0x00 0x88 0x13 0x14 0x34 0x00 0x0a
0x01 0x0a 0x02 0x0a 0x03 0x0a 0x04 0x0a 0x05 0x0a 0x06 0x0a 0x07 0x0a 0x08 0x0a
0x09 0x0a 0x0a 0x0a 0x0b 0x0a 0x0c 0x0a 0x0d 0x0a 0x0e 0x0a 0x0f 0x0a 0x10 0x0a
0x11 0x0a 0x12 0x0a 0x13 0x0a 0x14 0x0a 0x15 0x0a 0x16 0x0a 0x17 0x0a 0x18 0x0a
0x19 0x0a 0x1a 0x0a 0x1b 0x0a 0x89 0x01 0x3c 0x00 0x88 0x13 0x14 0x38 0x00 0x0a
0x01 0x0a 0x02 0x0a 0x03 0x0a 0x04 0x0a 0x05 0x0a 0x06 0x0a 0x07 0x0a 0x08 0x0a
0x09 0x0a 0x0a 0x0a 0x0b 0x0a 0x0c 0x0a 0x0d 0x0a 0x0e 0x0a 0x0f 0x0a 0x10 0x0a
0x11 0x0a 0x12 0x0a 0x13 0x0a 0x14 0x0a 0x15 0x0a 0x16 0x0a 0x17 0x0a 0x18 0x0a
0x19 0x0a 0x1a 0x0a 0x1b 0x0a 0x89 0x01 0x3c 0x00 0x88 0x13 0x14 0x3c 0x00 0x0a
0x01 0x0a 0x02 0x0a 0x03 0x0a 0x04 0x0a 0x05 0x0a 0x06 0x0a 0x07 0x0a 0x08 0x0a
0x09 0x0a 0x0a 0x0a 0x0b 0x0a 0x0c 0x0a 0x0d 0x0a 0x0e 0x0a 0x0f 0x0a 0x10 0x0a
0x11 0x0a 0x12 0x0a 0x13 0x0a 0x14 0x0a 0x15 0x0a 0x16 0x0a 0x17 0x0a 0x18 0x0a
0x19 0x0a 0x1a 0x0a 0x1b 0x0a 0x89 0x01 0x3c 0x00 0x88 0x13 0x14 0x40 0x00 0x0a
0x01 0x0a 0x02 0x0a 0x03 0x0a 0x04 0x0a 0x05 0x0a 0x06 0x0a 0x07 0x0a 0x08 0x0a
0x09 0x0a 0x0a 0x0a 0x0b 0x0a 0x0c 0x0a 0x0d 0x0a 0x0e 0x0a 0x0f 0x0a 0x10 0x0a
0x11 0x0a 0x12 0x0a 0x13 0x0a 0x14 0x0a 0x15 0x0a 0x16 0x0a 0x17 0x0a 0x18 0x0a
0x19 0x0a 0x1a 0x0a 0x1b 0x0a
	>;

	marvell,caldata_01_txpwrlimit_5g_cfg_set_sub1 = /bits/ 8 <
0x01 0x00 0x06 0x00 0x04 0x03 0x89 0x01 0x3c 0x00 0x88 0x13 0x14 0x64 0x00 0x0a
0x01 0x0a 0x02 0x0a 0x03 0x0a 0x04 0x0a 0x05 0x0a 0x06 0x0a 0x07 0x0a 0x08 0x0a
0x09 0x0a 0x0a 0x0a 0x0b 0x0a 0x0c 0x0a 0x0d 0x0a 0x0e 0x0a 0x0f 0x0a 0x10 0x0a
0x11 0x0a 0x12 0x0a 0x13 0x0a 0x14 0x0a 0x15 0x0a 0x16 0x0a 0x17 0x0a 0x18 0x0a
0x19 0x0a 0x1a 0x0a 0x1b 0x0a 0x89 0x01 0x3c 0x00 0x88 0x13 0x14 0x68 0x00 0x0a
0x01 0x0a 0x02 0x0a 0x03 0x0a 0x04 0x0a 0x05 0x0a 0x06 0x0a 0x07 0x0a 0x08 0x0a
0x09 0x0a 0x0a 0x0a 0x0b 0x0a 0x0c 0x0a 0x0d 0x0a 0x0e 0x0a 0x0f 0x0a 0x10 0x0a
0x11 0x0a 0x12 0x0a 0x13 0x0a 0x14 0x0a 0x15 0x0a 0x16 0x0a 0x17 0x0a 0x18 0x0a
0x19 0x0a 0x1a 0x0a 0x1b 0x0a 0x89 0x01 0x3c 0x00 0x88 0x13 0x14 0x6c 0x00 0x0a
0x01 0x0a 0x02 0x0a 0x03 0x0a 0x04 0x0a 0x05 0x0a 0x06 0x0a 0x07 0x0a 0x08 0x0a
0x09 0x0a 0x0a 0x0a 0x0b 0x0a 0x0c 0x0a 0x0d 0x0a 0x0e 0x0a 0x0f 0x0a 0x10 0x0a
0x11 0x0a 0x12 0x0a 0x13 0x0a 0x14 0x0a 0x15 0x0a 0x16 0x0a 0x17 0x0a 0x18 0x0a
0x19 0x0a 0x1a 0x0a 0x1b 0x0a 0x89 0x01 0x3c 0x00 0x88 0x13 0x14 0x70 0x00 0x0a
0x01 0x0a 0x02 0x0a 0x03 0x0a 0x04 0x0a 0x05 0x0a 0x06 0x0a 0x07 0x0a 0x08 0x0a
0x09 0x0a 0x0a 0x0a 0x0b 0x0a 0x0c 0x0a 0x0d 0x0a 0x0e 0x0a 0x0f 0x0a 0x10 0x0a
0x11 0x0a 0x12 0x0a 0x13 0x0a 0x14 0x0a 0x15 0x0a 0x16 0x0a 0x17 0x0a 0x18 0x0a
0x19 0x0a 0x1a 0x0a 0x1b 0x0a 0x89 0x01 0x3c 0x00 0x88 0x13 0x14 0x74 0x00 0x0a
0x01 0x0a 0x02 0x0a 0x03 0x0a 0x04 0x0a 0x05 0x0a 0x06 0x0a 0x07 0x0a 0x08 0x0a
0x09 0x0a 0x0a 0x0a 0x0b 0x0a 0x0c 0x0a 0x0d 0x0a 0x0e 0x0a 0x0f 0x0a 0x10 0x0a
0x11 0x0a 0x12 0x0a 0x13 0x0a 0x14 0x0a 0x15 0x0a 0x16 0x0a 0x17 0x0a 0x18 0x0a
0x19 0x0a 0x1a 0x0a 0x1b 0x0a 0x89 0x01 0x3c 0x00 0x88 0x13 0x14 0x78 0x00 0x0a
0x01 0x0a 0x02 0x0a 0x03 0x0a 0x04 0x0a 0x05 0x0a 0x06 0x0a 0x07 0x0a 0x08 0x0a
0x09 0x0a 0x0a 0x0a 0x0b 0x0a 0x0c 0x0a 0x0d 0x0a 0x0e 0x0a 0x0f 0x0a 0x10 0x0a
0x11 0x0a 0x12 0x0a 0x13 0x0a 0x14 0x0a 0x15 0x0a 0x16 0x0a 0x17 0x0a 0x18 0x0a
0x19 0x0a 0x1a 0x0a 0x1b 0x0a 0x89 0x01 0x3c 0x00 0x88 0x13 0x14 0x7c 0x00 0x0a
0x01 0x0a 0x02 0x0a 0x03 0x0a 0x04 0x0a 0x05 0x0a 0x06 0x0a 0x07 0x0a 0x08 0x0a
0x09 0x0a 0x0a 0x0a 0x0b 0x0a 0x0c 0x0a 0x0d 0x0a 0x0e 0x0a 0x0f 0x0a 0x10 0x0a
0x11 0x0a 0x12 0x0a 0x13 0x0a 0x14 0x0a 0x15 0x0a 0x16 0x0a 0x17 0x0a 0x18 0x0a
0x19 0x0a 0x1a 0x0a 0x1b 0x0a 0x89 0x01 0x3c 0x00 0x88 0x13 0x14 0x80 0x00 0x0a
0x01 0x0a 0x02 0x0a 0x03 0x0a 0x04 0x0a 0x05 0x0a 0x06 0x0a 0x07 0x0a 0x08 0x0a
0x09 0x0a 0x0a 0x0a 0x0b 0x0a 0x0c 0x0a 0x0d 0x0a 0x0e 0x0a 0x0f 0x0a 0x10 0x0a
0x11 0x0a 0x12 0x0a 0x13 0x0a 0x14 0x0a 0x15 0x0a 0x16 0x0a 0x17 0x0a 0x18 0x0a
0x19 0x0a 0x1a 0x0a 0x1b 0x0a 0x89 0x01 0x3c 0x00 0x88 0x13 0x14 0x84 0x00 0x0a
0x01 0x0a 0x02 0x0a 0x03 0x0a 0x04 0x0a 0x05 0x0a 0x06 0x0a 0x07 0x0a 0x08 0x0a
0x09 0x0a 0x0a 0x0a 0x0b 0x0a 0x0c 0x0a 0x0d 0x0a 0x0e 0x0a 0x0f 0x0a 0x10 0x0a
0x11 0x0a 0x12 0x0a 0x13 0x0a 0x14 0x0a 0x15 0x0a 0x16 0x0a 0x17 0x0a 0x18 0x0a
0x19 0x0a 0x1a 0x0a 0x1b 0x0a 0x89 0x01 0x3c 0x00 0x88 0x13 0x14 0x88 0x00 0x0a
0x01 0x0a 0x02 0x0a 0x03 0x0a 0x04 0x0a 0x05 0x0a 0x06 0x0a 0x07 0x0a 0x08 0x0a
0x09 0x0a 0x0a 0x0a 0x0b 0x0a 0x0c 0x0a 0x0d 0x0a 0x0e 0x0a 0x0f 0x0a 0x10 0x0a
0x11 0x0a 0x12 0x0a 0x13 0x0a 0x14 0x0a 0x15 0x0a 0x16 0x0a 0x17 0x0a 0x18 0x0a
0x19 0x0a 0x1a 0x0a 0x1b 0x0a 0x89 0x01 0x3c 0x00 0x88 0x13 0x14 0x8c 0x00 0x0a
0x01 0x0a 0x02 0x0a 0x03 0x0a 0x04 0x0a 0x05 0x0a 0x06 0x0a 0x07 0x0a 0x08 0x0a
0x09 0x0a 0x0a 0x0a 0x0b 0x0a 0x0c 0x0a 0x0d 0x0a 0x0e 0x0a 0x0f 0x0a 0x10 0x0a
0x11 0x0a 0x12 0x0a 0x13 0x0a 0x14 0x0a 0x15 0x0a 0x16 0x0a 0x17 0x0a 0x18 0x0a
0x19 0x0a 0x1a 0x0a 0x1b 0x0a 0x89 0x01 0x3c 0x00 0x88 0x13 0x14 0x90 0x00 0x0a
0x01 0x0a 0x02 0x0a 0x03 0x0a 0x04 0x0a 0x05 0x0a 0x06 0x0a 0x07 0x0a 0x08 0x0a
0x09 0x0a 0x0a 0x0a 0x0b 0x0a 0x0c 0x0a 0x0d 0x0a 0x0e 0x0a 0x0f 0x0a 0x10 0x0a
0x11 0x0a 0x12 0x0a 0x13 0x0a 0x14 0x0a 0x15 0x0a 0x16 0x0a 0x17 0x0a 0x18 0x0a
0x19 0x0a 0x1a 0x0a 0x1b 0x0a
	>;

	marvell,caldata_01_txpwrlimit_5g_cfg_set_sub2 = /bits/ 8 <
0x01 0x00 0x06 0x00 0x44 0x01 0x89 0x01 0x3c 0x00 0x88 0x13 0x14 0x95 0x00 0x0a
0x01 0x0a 0x02 0x0a 0x03 0x0a 0x04 0x0a 0x05 0x0a 0x06 0x0a 0x07 0x0a 0x08 0x0a
0x09 0x0a 0x0a 0x0a 0x0b 0x0a 0x0c 0x0a 0x0d 0x0a 0x0e 0x0a 0x0f 0x0a 0x10 0x0a
0x11 0x0a 0x12 0x0a 0x13 0x0a 0x14 0x0a 0x15 0x0a 0x16 0x0a 0x17 0x0a 0x18 0x0a
0x19 0x0a 0x1a 0x0a 0x1b 0x0a 0x89 0x01 0x3c 0x00 0x88 0x13 0x14 0x99 0x00 0x0a
0x01 0x0a 0x02 0x0a 0x03 0x0a 0x04 0x0a 0x05 0x0a 0x06 0x0a 0x07 0x0a 0x08 0x0a
0x09 0x0a 0x0a 0x0a 0x0b 0x0a 0x0c 0x0a 0x0d 0x0a 0x0e 0x0a 0x0f 0x0a 0x10 0x0a
0x11 0x0a 0x12 0x0a 0x13 0x0a 0x14 0x0a 0x15 0x0a 0x16 0x0a 0x17 0x0a 0x18 0x0a
0x19 0x0a 0x1a 0x0a 0x1b 0x0a 0x89 0x01 0x3c 0x00 0x88 0x13 0x14 0x9d 0x00 0x0a
0x01 0x0a 0x02 0x0a 0x03 0x0a 0x04 0x0a 0x05 0x0a 0x06 0x0a 0x07 0x0a 0x08 0x0a
0x09 0x0a 0x0a 0x0a 0x0b 0x0a 0x0c 0x0a 0x0d 0x0a 0x0e 0x0a 0x0f 0x0a 0x10 0x0a
0x11 0x0a 0x12 0x0a 0x13 0x0a 0x14 0x0a 0x15 0x0a 0x16 0x0a 0x17 0x0a 0x18 0x0a
0x19 0x0a 0x1a 0x0a 0x1b 0x0a 0x89 0x01 0x3c 0x00 0x88 0x13 0x14 0xa1 0x00 0x0a
0x01 0x0a 0x02 0x0a 0x03 0x0a 0x04 0x0a 0x05 0x0a 0x06 0x0a 0x07 0x0a 0x08 0x0a
0x09 0x0a 0x0a 0x0a 0x0b 0x0a 0x0c 0x0a 0x0d 0x0a 0x0e 0x0a 0x0f 0x0a 0x10 0x0a
0x11 0x0a 0x12 0x0a 0x13 0x0a 0x14 0x0a 0x15 0x0a 0x16 0x0a 0x17 0x0a 0x18 0x0a
0x19 0x0a 0x1a 0x0a 0x1b 0x0a 0x89 0x01 0x3c 0x00 0x88 0x13 0x14 0xa5 0x00 0x0a
0x01 0x0a 0x02 0x0a 0x03 0x0a 0x04 0x0a 0x05 0x0a 0x06 0x0a 0x07 0x0a 0x08 0x0a
0x09 0x0a 0x0a 0x0a 0x0b 0x0a 0x0c 0x0a 0x0d 0x0a 0x0e 0x0a 0x0f 0x0a 0x10 0x0a
0x11 0x0a 0x12 0x0a 0x13 0x0a 0x14 0x0a 0x15 0x0a 0x16 0x0a 0x17 0x0a 0x18 0x0a
0x19 0x0a 0x1a 0x0a 0x1b 0x0a
	>;

	marvell,caldata_01_txpwrlimit_5g_cfg_set_sub3 = /bits/ 8 <
0x01 0x00 0x06 0x00 0x84 0x03 0x89 0x01 0x3c 0x00 0xa0 0x0f 0x14 0xb7 0x00 0x0a
0x01 0x0a 0x02 0x0a 0x03 0x0a 0x04 0x0a 0x05 0x0a 0x06 0x0a 0x07 0x0a 0x08 0x0a
0x09 0x0a 0x0a 0x0a 0x0b 0x0a 0x0c 0x0a 0x0d 0x0a 0x0e 0x0a 0x0f 0x0a 0x10 0x0a
0x11 0x0a 0x12 0x0a 0x13 0x0a 0x14 0x0a 0x15 0x0a 0x16 0x0a 0x17 0x0a 0x18 0x0a
0x19 0x0a 0x1a 0x0a 0x1b 0x0a 0x89 0x01 0x3c 0x00 0xa0 0x0f 0x14 0xb8 0x00 0x0a
0x01 0x0a 0x02 0x0a 0x03 0x0a 0x04 0x0a 0x05 0x0a 0x06 0x0a 0x07 0x0a 0x08 0x0a
0x09 0x0a 0x0a 0x0a 0x0b 0x0a 0x0c 0x0a 0x0d 0x0a 0x0e 0x0a 0x0f 0x0a 0x10 0x0a
0x11 0x0a 0x12 0x0a 0x13 0x0a 0x14 0x0a 0x15 0x0a 0x16 0x0a 0x17 0x0a 0x18 0x0a
0x19 0x0a 0x1a 0x0a 0x1b 0x0a 0x89 0x01 0x3c 0x00 0xa0 0x0f 0x14 0xb9 0x00 0x0a
0x01 0x0a 0x02 0x0a 0x03 0x0a 0x04 0x0a 0x05 0x0a 0x06 0x0a 0x07 0x0a 0x08 0x0a
0x09 0x0a 0x0a 0x0a 0x0b 0x0a 0x0c 0x0a 0x0d 0x0a 0x0e 0x0a 0x0f 0x0a 0x10 0x0a
0x11 0x0a 0x12 0x0a 0x13 0x0a 0x14 0x0a 0x15 0x0a 0x16 0x0a 0x17 0x0a 0x18 0x0a
0x19 0x0a 0x1a 0x0a 0x1b 0x0a 0x89 0x01 0x3c 0x00 0xa0 0x0f 0x14 0xbb 0x00 0x0a
0x01 0x0a 0x02 0x0a 0x03 0x0a 0x04 0x0a 0x05 0x0a 0x06 0x0a 0x07 0x0a 0x08 0x0a
0x09 0x0a 0x0a 0x0a 0x0b 0x0a 0x0c 0x0a 0x0d 0x0a 0x0e 0x0a 0x0f 0x0a 0x10 0x0a
0x11 0x0a 0x12 0x0a 0x13 0x0a 0x14 0x0a 0x15 0x0a 0x16 0x0a 0x17 0x0a 0x18 0x0a
0x19 0x0a 0x1a 0x0a 0x1b 0x0a 0x89 0x01 0x3c 0x00 0xa0 0x0f 0x14 0xbc 0x00 0x0a
0x01 0x0a 0x02 0x0a 0x03 0x0a 0x04 0x0a 0x05 0x0a 0x06 0x0a 0x07 0x0a 0x08 0x0a
0x09 0x0a 0x0a 0x0a 0x0b 0x0a 0x0c 0x0a 0x0d 0x0a 0x0e 0x0a 0x0f 0x0a 0x10 0x0a
0x11 0x0a 0x12 0x0a 0x13 0x0a 0x14 0x0a 0x15 0x0a 0x16 0x0a 0x17 0x0a 0x18 0x0a
0x19 0x0a 0x1a 0x0a 0x1b 0x0a 0x89 0x01 0x3c 0x00 0xa0 0x0f 0x14 0xbd 0x00 0x0a
0x01 0x0a 0x02 0x0a 0x03 0x0a 0x04 0x0a 0x05 0x0a 0x06 0x0a 0x07 0x0a 0x08 0x0a
0x09 0x0a 0x0a 0x0a 0x0b 0x0a 0x0c 0x0a 0x0d 0x0a 0x0e 0x0a 0x0f 0x0a 0x10 0x0a
0x11 0x0a 0x12 0x0a 0x13 0x0a 0x14 0x0a 0x15 0x0a 0x16 0x0a 0x17 0x0a 0x18 0x0a
0x19 0x0a 0x1a 0x0a 0x1b 0x0a 0x89 0x01 0x3c 0x00 0xa0 0x0f 0x14 0xc0 0x00 0x0a
0x01 0x0a 0x02 0x0a 0x03 0x0a 0x04 0x0a 0x05 0x0a 0x06 0x0a 0x07 0x0a 0x08 0x0a
0x09 0x0a 0x0a 0x0a 0x0b 0x0a 0x0c 0x0a 0x0d 0x0a 0x0e 0x0a 0x0f 0x0a 0x10 0x0a
0x11 0x0a 0x12 0x0a 0x13 0x0a 0x14 0x0a 0x15 0x0a 0x16 0x0a 0x17 0x0a 0x18 0x0a
0x19 0x0a 0x1a 0x0a 0x1b 0x0a 0x89 0x01 0x3c 0x00 0xa0 0x0f 0x14 0xc4 0x00 0x0a
0x01 0x0a 0x02 0x0a 0x03 0x0a 0x04 0x0a 0x05 0x0a 0x06 0x0a 0x07 0x0a 0x08 0x0a
0x09 0x0a 0x0a 0x0a 0x0b 0x0a 0x0c 0x0a 0x0d 0x0a 0x0e 0x0a 0x0f 0x0a 0x10 0x0a
0x11 0x0a 0x12 0x0a 0x13 0x0a 0x14 0x0a 0x15 0x0a 0x16 0x0a 0x17 0x0a 0x18 0x0a
0x19 0x0a 0x1a 0x0a 0x1b 0x0a 0x89 0x01 0x3c 0x00 0x88 0x13 0x14 0x07 0x00 0x0a
0x01 0x0a 0x02 0x0a 0x03 0x0a 0x04 0x0a 0x05 0x0a 0x06 0x0a 0x07 0x0a 0x08 0x0a
0x09 0x0a 0x0a 0x0a 0x0b 0x0a 0x0c 0x0a 0x0d 0x0a 0x0e 0x0a 0x0f 0x0a 0x10 0x0a
0x11 0x0a 0x12 0x0a 0x13 0x0a 0x14 0x0a 0x15 0x0a 0x16 0x0a 0x17 0x0a 0x18 0x0a
0x19 0x0a 0x1a 0x0a 0x1b 0x0a 0x89 0x01 0x3c 0x00 0x88 0x13 0x14 0x08 0x00 0x0a
0x01 0x0a 0x02 0x0a 0x03 0x0a 0x04 0x0a 0x05 0x0a 0x06 0x0a 0x07 0x0a 0x08 0x0a
0x09 0x0a 0x0a 0x0a 0x0b 0x0a 0x0c 0x0a 0x0d 0x0a 0x0e 0x0a 0x0f 0x0a 0x10 0x0a
0x11 0x0a 0x12 0x0a 0x13 0x0a 0x14 0x0a 0x15 0x0a 0x16 0x0a 0x17 0x0a 0x18 0x0a
0x19 0x0a 0x1a 0x0a 0x1b 0x0a 0x89 0x01 0x3c 0x00 0x88 0x13 0x14 0x0b 0x00 0x0a
0x01 0x0a 0x02 0x0a 0x03 0x0a 0x04 0x0a 0x05 0x0a 0x06 0x0a 0x07 0x0a 0x08 0x0a
0x09 0x0a 0x0a 0x0a 0x0b 0x0a 0x0c 0x0a 0x0d 0x0a 0x0e 0x0a 0x0f 0x0a 0x10 0x0a
0x11 0x0a 0x12 0x0a 0x13 0x0a 0x14 0x0a 0x15 0x0a 0x16 0x0a 0x17 0x0a 0x18 0x0a
0x19 0x0a 0x1a 0x0a 0x1b 0x0a 0x89 0x01 0x3c 0x00 0x88 0x13 0x14 0x0c 0x00 0x0a
0x01 0x0a 0x02 0x0a 0x03 0x0a 0x04 0x0a 0x05 0x0a 0x06 0x0a 0x07 0x0a 0x08 0x0a
0x09 0x0a 0x0a 0x0a 0x0b 0x0a 0x0c 0x0a 0x0d 0x0a 0x0e 0x0a 0x0f 0x0a 0x10 0x0a
0x11 0x0a 0x12 0x0a 0x13 0x0a 0x14 0x0a 0x15 0x0a 0x16 0x0a 0x17 0x0a 0x18 0x0a
0x19 0x0a 0x1a 0x0a 0x1b 0x0a 0x89 0x01 0x3c 0x00 0x88 0x13 0x14 0x10 0x00 0x0a
0x01 0x0a 0x02 0x0a 0x03 0x0a 0x04 0x0a 0x05 0x0a 0x06 0x0a 0x07 0x0a 0x08 0x0a
0x09 0x0a 0x0a 0x0a 0x0b 0x0a 0x0c 0x0a 0x0d 0x0a 0x0e 0x0a 0x0f 0x0a 0x10 0x0a
0x11 0x0a 0x12 0x0a 0x13 0x0a 0x14 0x0a 0x15 0x0a 0x16 0x0a 0x17 0x0a 0x18 0x0a
0x19 0x0a 0x1a 0x0a 0x1b 0x0a 0x89 0x01 0x3c 0x00 0x88 0x13 0x14 0x22 0x00 0x0a
0x01 0x0a 0x02 0x0a 0x03 0x0a 0x04 0x0a 0x05 0x0a 0x06 0x0a 0x07 0x0a 0x08 0x0a
0x09 0x0a 0x0a 0x0a 0x0b 0x0a 0x0c 0x0a 0x0d 0x0a 0x0e 0x0a 0x0f 0x0a 0x10 0x0a
0x11 0x0a 0x12 0x0a 0x13 0x0a 0x14 0x0a 0x15 0x0a 0x16 0x0a 0x17 0x0a 0x18 0x0a
0x19 0x0a 0x1a 0x0a 0x1b 0x0a
	>;
};
